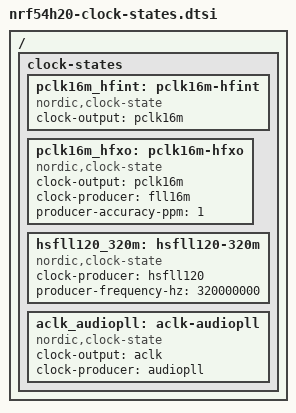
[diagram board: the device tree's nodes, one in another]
/*
 * Copyright (c) 2026 Nordic Semiconductor ASA
 *
 * SPDX-License-Identifier: Apache-2.0
 */

/* Clock states of the nRF54H20 clocks. Each state is a pure descriptor selected by a consumer's
 * `clocks` property; it is /omit-if-no-ref/ so it costs nothing until referenced. Included at the
 * end of the SoC devicetree, after the referenced outputs and producers.
 */

/ {
	clock-states {
		/* States of the 16 MHz peripheral clock, which is generated by fll16m. Both run the
		 * peripheral at the same frequency; they differ in whether fll16m is requested:
		 *   - hfint: no producer. fll16m's open-loop (low-accuracy) mode is the default the
		 *            peripheral runs off automatically, so no runtime action is taken - the
		 *            same way pclk16m_hfint has no producer on nRF53/nRF54L.
		 *   - hfxo:  requests fll16m with producer-accuracy-ppm = <1>
		 *            (NRF_CLOCK_CONTROL_ACCURACY_MAX), which selects the HFXO-bypass source
		 *            for bitrate accuracy.
		 */
		/omit-if-no-ref/ pclk16m_hfint: pclk16m-hfint {
			compatible = "nordic,clock-state";
			#clock-cells = <0>;
			clock-output = <&pclk16m>;
		};

		/omit-if-no-ref/ pclk16m_hfxo: pclk16m-hfxo {
			compatible = "nordic,clock-state";
			#clock-cells = <0>;
			clock-output = <&pclk16m>;
			clock-producer = <&fll16m>;
			producer-accuracy-ppm = <1>;
		};

		/* State for a fast peripheral clocked directly by the hsfll120 global HSFLL. hsfll120
		 * is a frequency-selectable (DVFS) generator with no fixed output rail, so the state
		 * has no clock-output: the frequency the peripheral runs at is the requested operating
		 * point, given by producer-frequency-hz and passed as the nrf_clock_spec frequency.
		 * Selecting it requests hsfll120 at 320 MHz (the highest supported operating point).
		 */
		/omit-if-no-ref/ hsfll120_320m: hsfll120-320m {
			compatible = "nordic,clock-state";
			#clock-cells = <0>;
			clock-producer = <&hsfll120>;
			producer-frequency-hz = <320000000>;
		};

		/* Audio clock. The aclk signal advertises the target audio frequency (owned by the
		 * audiopll producer, whose clock-frequency gives the rate in Hz); the audiopll is
		 * requested and driven to that rate. A single state, always PLL-backed. Used by audio
		 * peripherals (TDM130, PDM130) for the ACLK mux position, alongside the pclk16m states
		 * for the PCLK mux position.
		 */
		/omit-if-no-ref/ aclk_audiopll: aclk-audiopll {
			compatible = "nordic,clock-state";
			#clock-cells = <0>;
			clock-output = <&aclk>;
			clock-producer = <&audiopll>;
		};
	};
};
